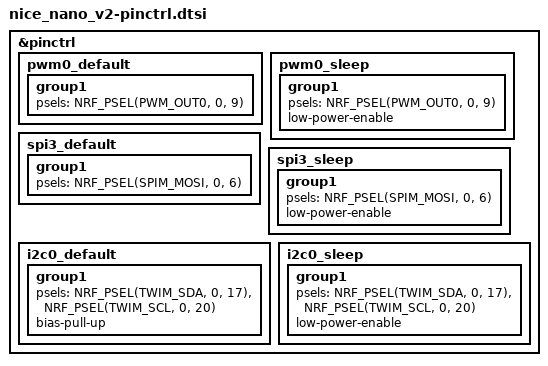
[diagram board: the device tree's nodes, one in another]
#include <dt-bindings/pinctrl/nrf-pinctrl.h>

&pinctrl {
    // Configuração dos pinos para o PWM (backlight)
    pwm0_default: pwm0_default {
        group1 {
            psels = <NRF_PSEL(PWM_OUT0, 0, 9)>;
        };
    };

    pwm0_sleep: pwm0_sleep {
        group1 {
            psels = <NRF_PSEL(PWM_OUT0, 0, 9)>;
            low-power-enable;
        };
    };

    // Configuração para SPI (underglow RGB)
    spi3_default: spi3_default {
        group1 {
            psels = <NRF_PSEL(SPIM_MOSI, 0, 6)>;
        };
    };

    spi3_sleep: spi3_sleep {
        group1 {
            psels = <NRF_PSEL(SPIM_MOSI, 0, 6)>;
            low-power-enable;
        };
    };

    // Configuração para I2C (display OLED)
    i2c0_default: i2c0_default {
        group1 {
            psels = <NRF_PSEL(TWIM_SDA, 0, 17)>,
                   <NRF_PSEL(TWIM_SCL, 0, 20)>;
            bias-pull-up;
        };
    };

    i2c0_sleep: i2c0_sleep {
        group1 {
            psels = <NRF_PSEL(TWIM_SDA, 0, 17)>,
                   <NRF_PSEL(TWIM_SCL, 0, 20)>;
            low-power-enable;
        };
    };
};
